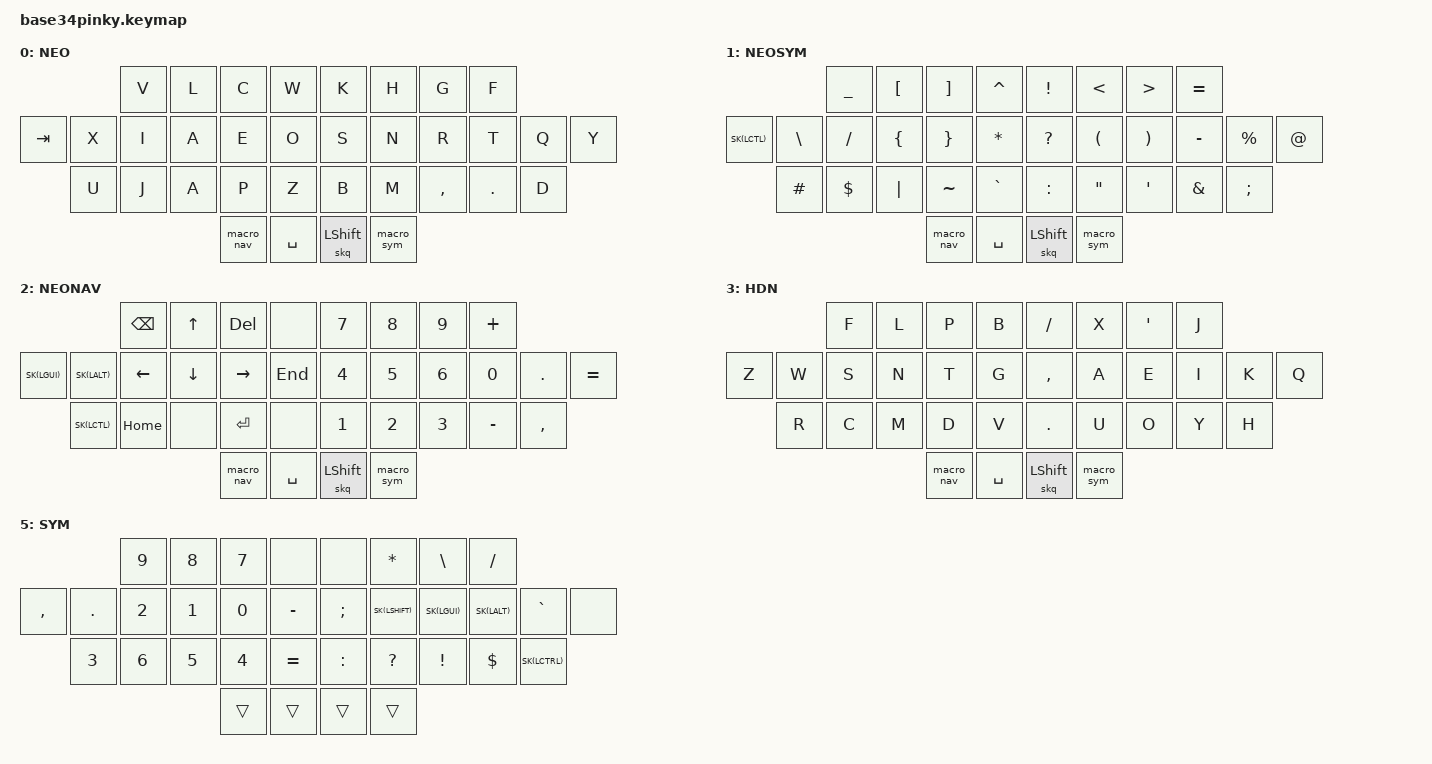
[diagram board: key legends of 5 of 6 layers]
/*
 * Copyright (c) 2020 The ZMK Contributors
 *
 * SPDX-License-Identifier: MIT
 */

#include <behaviors.dtsi>
#include <dt-bindings/zmk/keys.h>
#include <dt-bindings/zmk/bt.h>
#include <dt-bindings/zmk/outputs.h>

#define NEO 0
#define NEOSYM 1
#define NEONAV 2
#define HDN 3
#define NAV 4
#define SYM 5

#define SK(KEY) &nk KEY KEY
// Keep sticky keys active for a long time so they effectively do not time out
#define STICKY_KEY_TIMEOUT 60000

&sk {
  release-after-ms = <STICKY_KEY_TIMEOUT>;
};

&caps_word {
  continue-list = <UNDERSCORE MINUS BACKSPACE>;
};

/* KEY POSITIONS
  ╭───────────────────────╮          ╭───────────────────────╮
  │          0   1   2  3 │          │  4   5   6   7        │
  │  8   9  10  11  12 13 │          │ 14  15  16  17  18  19│
  │     20  21  22  23 24  ───╮ ╭────  25  26  27  28  29    │
  ╰─────────────────╮  30  31 │ │ 32  33 ╭───────────────────╯
                    ╰─────────╯ ╰────────╯           
*/

/ { 
  
                
  combos {
    #include "combos.dtsi"
  };
  
  macros {
    #include "macros.dtsi"
  };

  behaviors {
    // Sticky key on tap, normal key on hold
    // Useful for modifier-clicking without the modifier remaining active
     nk: not_so_sticky_key {
       compatible = "zmk,behavior-hold-tap";
       label = "NOT_SO_STICKY_KEY";
       #binding-cells = <2>;
       tapping_term_ms = <200>;
       flavor = "tap-preferred";
       bindings = <&kp>, <&sk>;
     };

    skq: sticky_key_quick_release {
      compatible = "zmk,behavior-sticky-key";
      label = "STICKY_KEY_QUICK_RELEASE";
      #binding-cells = <1>;
      bindings = <&kp>;
      quick-release;
      release-after-ms = <STICKY_KEY_TIMEOUT>;
    };


  };
 
        keymap {
                compatible = "zmk,keymap";

        neoalpha {
        label = "NEO";
        bindings = <
// TODO Find a place for missing letters: Ü, Ö, Ä, (ẞ) - find the names
// ╭─────────────┬─────────────┬─────────────┬─────────────┬─────────────╮   ╭─────────────┬─────────────┬─────────────┬─────────────┬─────────────╮
                      &kp V         &kp L         &kp C         &kp W             &kp K       &kp H         &kp G         &kp F
&kp TAB &kp X         &kp I         &kp A         &kp E         &kp O             &kp S       &kp N         &kp R         &kp T         &kp Q        &kp Y
        &kp U         &kp J         &kp A         &kp P         &kp Z             &kp B       &kp M         &kp COMMA     &kp DOT       &kp D
// ╰─────────────┴─────────────┴─────────────┼─────────────┼─────────────┤   ├─────────────┼─────────────┼─────────────┴─────────────┴─────────────╯
                                               &macro_nav    &kp SPACE         &skq LSHIFT    &macro_sym
//                                           ╰─────────────┴─────────────╯   ╰─────────────┴─────────────╯
        >;
        };

        neosym {
        label = "NEOSYM";
        bindings = <
// TODO Find a place for missing symbols:
// ╭─────────────┬─────────────┬─────────────┬─────────────┬─────────────╮         ╭─────────────┬─────────────┬─────────────┬─────────────┬─────────────╮
                       &kp UNDERSCORE &kp LEFT_BRACKET &kp RIGHT_BRACKET &kp CARET    &kp EXCLAMATION &kp LESS_THAN        &kp GREATER_THAN      &kp EQUAL
SK(LCTL) &kp BACKSLASH &kp SLASH      &kp LEFT_BRACE   &kp RIGHT_BRACE   &kp ASTERISK &kp QUESTION    &kp LEFT_PARENTHESIS &kp RIGHT_PARENTHESIS &kp MINUS     &kp PERCENT   &kp AT_SIGN
         &kp HASH      &kp DOLLAR     &kp PIPE         &kp TILDE         &kp GRAVE    &kp COLON       &kp DOUBLE_QUOTES    &kp SINGLE_QUOTE      &kp AMPERSAND &kp SEMICOLON
// ╰─────────────┴─────────────┴─────────────┼─────────────┼─────────────┤         ├─────────────┼─────────────┼─────────────┴─────────────┴─────────────╯
                                               &macro_nav    &kp SPACE              &skq LSHIFT    &macro_sym
//                                           ╰─────────────┴─────────────╯         ╰─────────────┴─────────────╯
        >;
        };

        neonav {
        label = "NEONAV";
        bindings = <
// ╭─────────────┬─────────────┬─────────────┬─────────────┬─────────────╮         ╭─────────────┬─────────────┬─────────────┬─────────────┬─────────────╮
                    &kp BACKSPACE &kp UP      &kp DELETE     &none                  &kp N7        &kp N8        &kp N9        &kp PLUS
SK(LGUI) SK(LALT)   &kp LEFT      &kp DOWN    &kp RIGHT      &kp END                &kp N4        &kp N5        &kp N6        &kp N0        &kp DOT  &kp EQUAL
         SK(LCTL)   &kp HOME      &none       &kp RETURN     &none                  &kp N1        &kp N2        &kp N3        &kp MINUS     &kp COMMA
// ╰─────────────┴─────────────┴─────────────┼─────────────┼─────────────┤         ├─────────────┼─────────────┼─────────────┴─────────────┴─────────────╯
                                               &macro_nav    &kp SPACE              &skq LSHIFT    &macro_sym
//                                           ╰─────────────┴─────────────╯         ╰─────────────┴─────────────╯
        >;
        };


// TODO ADAPT TO NEO2 Layout
        handsdown {
            label = "HDN";
            bindings = <
// ╭─────────────┬─────────────┬─────────────┬─────────────┬─────────────╮   ╭─────────────┬─────────────┬─────────────┬─────────────┬─────────────╮
                      &kp F         &kp L         &kp P         &kp B             &kp SLASH     &kp X         &kp SQT       &kp J
&kp Z   &kp W         &kp S         &kp N         &kp T         &kp G             &kp COMMA     &kp A         &kp E         &kp I         &kp K  &kp Q
        &kp R         &kp C         &kp M         &kp D         &kp V             &kp DOT       &kp U         &kp O         &kp Y         &kp H
// ╰─────────────┴─────────────┴─────────────┼─────────────┼─────────────┤   ├─────────────┼─────────────┼─────────────┴─────────────┴─────────────╯
                                               &macro_nav    &kp SPACE         &skq LSHIFT    &macro_sym
//                                           ╰─────────────┴─────────────╯   ╰─────────────┴─────────────╯
            >;
        };

// INFO Alaa uses it for the arrows
        navitation {
            label = "NAV";
            bindings = <
// ╭─────────────┬─────────────┬─────────────┬─────────────┬─────────────╮   ╭─────────────┬─────────────┬─────────────┬─────────────┬─────────────╮
                    &kp ENTER     &kp BACKSPACE  &kp TAB       &kp LA(BACKSPACE)  &kp LA(BACKSPACE) &none         &kp UP        &kp LG(Q)     
&none   &none       SK(LALT)      SK(LGUI)       SK(LSHIFT)    &kp DELETE         &none             &kp LEFT      &kp DOWN      &kp RIGHT     &none &none
        SK(LCTL)    &kp LG(X)     &kp LG(C)      &kp LG(V)     &kp LG(A)          &kp LG(A)         &kp ENTER     &kp BACKSPACE &kp TAB       &kp LG(LC(LA(LS(P))))
// ╰─────────────┴─────────────┴─────────────┼─────────────┼─────────────┤   ├─────────────┼─────────────┼─────────────┴─────────────┴─────────────╯
                                               &trans         &trans            &trans        &trans
//                                           ╰─────────────┴─────────────╯   ╰─────────────┴─────────────╯
            >;
        };
        symbols {
            label = "SYM";
            bindings = <
// ╭─────────────┬─────────────┬─────────────┬─────────────┬─────────────╮   ╭─────────────┬─────────────┬─────────────┬─────────────┬─────────────╮
                      &kp N9       &kp N8         &kp N7         &none             &none        &kp ASTRK     &kp BSLH     &kp SLASH     
&kp COMMA  &kp DOT    &kp N2       &kp N1         &kp N0         &kp MINUS         &kp SEMI     SK(LSHIFT)    SK(LGUI)     SK(LALT)      &kp GRAVE &none
           &kp N3     &kp N6       &kp N5         &kp N4         &kp EQUAL         &kp COLON    &kp QMARK     &kp EXCL     &kp DLLR      SK(LCTRL) 
// ╰─────────────┴─────────────┴─────────────┼─────────────┼─────────────┤   ├─────────────┼─────────────┼─────────────┴─────────────┴─────────────╯
                                               &trans         &trans            &trans       &trans
//                                           ╰─────────────┴─────────────╯   ╰─────────────┴─────────────╯
            >;
        };


};

};
